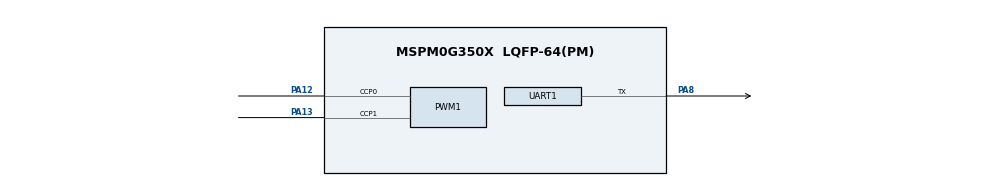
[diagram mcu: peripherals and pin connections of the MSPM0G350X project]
/**
 * @cliArgs --device "MSPM0G350X" --package "LQFP-64(PM)" --part "Default" --product "mspm0_sdk@2.01.00.03"
 * @versions {"tool":"1.20.0+3587"}
 */

/**
 * Import the modules used in this configuration.
 */
const GPIO   = scripting.addModule("/ti/driverlib/GPIO", {}, false);
const GPIO1  = GPIO.addInstance();
const GPIO2  = GPIO.addInstance();
const GPIO3  = GPIO.addInstance();
const GPIO4  = GPIO.addInstance();
const GPIO5  = GPIO.addInstance();
const GPIO6  = GPIO.addInstance();
const GPIO7  = GPIO.addInstance();
const GPIO8  = GPIO.addInstance();
const PWM    = scripting.addModule("/ti/driverlib/PWM", {}, false);
const PWM1   = PWM.addInstance();
const SYSCTL = scripting.addModule("/ti/driverlib/SYSCTL");
const TIMER  = scripting.addModule("/ti/driverlib/TIMER", {}, false);
const TIMER1 = TIMER.addInstance();
const UART   = scripting.addModule("/ti/driverlib/UART", {}, false);
const UART1  = UART.addInstance();

/**
 * Write custom configuration values to the imported modules.
 */
GPIO1.$name                          = "GPIO_OLED";
GPIO1.associatedPins.create(2);
GPIO1.associatedPins[0].$name        = "SCL";
GPIO1.associatedPins[0].initialValue = "SET";
GPIO1.associatedPins[0].assignedPort = "PORTB";
GPIO1.associatedPins[0].assignedPin  = "6";
GPIO1.associatedPins[1].$name        = "SDA";
GPIO1.associatedPins[1].initialValue = "SET";
GPIO1.associatedPins[1].assignedPort = "PORTB";
GPIO1.associatedPins[1].assignedPin  = "1";

const Board = scripting.addModule("/ti/driverlib/Board", {}, false);

GPIO2.$name                          = "GPIO_LEFT_DIR";
GPIO2.associatedPins.create(2);
GPIO2.associatedPins[0].assignedPort = "PORTA";
GPIO2.associatedPins[0].assignedPin  = "28";
GPIO2.associatedPins[0].$name        = "IN1";
GPIO2.associatedPins[1].assignedPort = "PORTA";
GPIO2.associatedPins[1].assignedPin  = "31";
GPIO2.associatedPins[1].$name        = "IN2";

GPIO3.$name                          = "GPIO_RIGHT_DIR";
GPIO3.associatedPins.create(2);
GPIO3.associatedPins[0].$name        = "IN3";
GPIO3.associatedPins[0].assignedPort = "PORTB";
GPIO3.associatedPins[0].assignedPin  = "12";
GPIO3.associatedPins[1].$name        = "IN4";
GPIO3.associatedPins[1].assignedPort = "PORTB";
GPIO3.associatedPins[1].assignedPin  = "17";

GPIO4.$name                               = "GPIO_ECD";
GPIO4.associatedPins.create(4);
GPIO4.associatedPins[0].direction         = "INPUT";
GPIO4.associatedPins[0].assignedPort      = "PORTB";
GPIO4.associatedPins[0].assignedPin       = "15";
GPIO4.associatedPins[0].interruptEn       = true;
GPIO4.associatedPins[0].interruptPriority = "0";
GPIO4.associatedPins[0].polarity          = "RISE";
GPIO4.associatedPins[0].$name             = "LEFT_A";
GPIO4.associatedPins[1].direction         = "INPUT";
GPIO4.associatedPins[1].assignedPort      = "PORTB";
GPIO4.associatedPins[1].assignedPin       = "13";
GPIO4.associatedPins[1].polarity          = "RISE";
GPIO4.associatedPins[1].interruptEn       = true;
GPIO4.associatedPins[1].interruptPriority = "0";
GPIO4.associatedPins[1].$name             = "LEFT_B";
GPIO4.associatedPins[2].$name             = "RIGH_A";
GPIO4.associatedPins[2].direction         = "INPUT";
GPIO4.associatedPins[2].interruptEn       = true;
GPIO4.associatedPins[2].interruptPriority = "0";
GPIO4.associatedPins[2].polarity          = "RISE";
GPIO4.associatedPins[2].assignedPort      = "PORTB";
GPIO4.associatedPins[2].assignedPin       = "8";
GPIO4.associatedPins[3].$name             = "RIGH_B";
GPIO4.associatedPins[3].direction         = "INPUT";
GPIO4.associatedPins[3].assignedPort      = "PORTB";
GPIO4.associatedPins[3].assignedPin       = "7";
GPIO4.associatedPins[3].interruptEn       = true;
GPIO4.associatedPins[3].interruptPriority = "0";
GPIO4.associatedPins[3].polarity          = "RISE";

GPIO5.$name                          = "GPIO_TRK";
GPIO5.associatedPins.create(8);
GPIO5.associatedPins[0].$name        = "P0";
GPIO5.associatedPins[0].direction    = "INPUT";
GPIO5.associatedPins[0].assignedPort = "PORTB";
GPIO5.associatedPins[0].assignedPin  = "18";
GPIO5.associatedPins[1].$name        = "P1";
GPIO5.associatedPins[1].direction    = "INPUT";
GPIO5.associatedPins[1].assignedPort = "PORTB";
GPIO5.associatedPins[1].assignedPin  = "19";
GPIO5.associatedPins[2].$name        = "P2";
GPIO5.associatedPins[2].direction    = "INPUT";
GPIO5.associatedPins[2].assignedPort = "PORTB";
GPIO5.associatedPins[2].assignedPin  = "20";
GPIO5.associatedPins[3].$name        = "P3";
GPIO5.associatedPins[3].direction    = "INPUT";
GPIO5.associatedPins[3].assignedPort = "PORTB";
GPIO5.associatedPins[3].assignedPin  = "21";
GPIO5.associatedPins[4].$name        = "P4";
GPIO5.associatedPins[4].direction    = "INPUT";
GPIO5.associatedPins[4].assignedPort = "PORTB";
GPIO5.associatedPins[4].assignedPin  = "22";
GPIO5.associatedPins[5].$name        = "P5";
GPIO5.associatedPins[5].direction    = "INPUT";
GPIO5.associatedPins[5].assignedPort = "PORTB";
GPIO5.associatedPins[5].assignedPin  = "23";
GPIO5.associatedPins[6].$name        = "P6";
GPIO5.associatedPins[6].direction    = "INPUT";
GPIO5.associatedPins[6].assignedPort = "PORTB";
GPIO5.associatedPins[6].assignedPin  = "24";
GPIO5.associatedPins[7].$name        = "P7";
GPIO5.associatedPins[7].direction    = "INPUT";
GPIO5.associatedPins[7].assignedPort = "PORTB";
GPIO5.associatedPins[7].assignedPin  = "25";

GPIO6.$name                              = "GPIO_KEY";
GPIO6.associatedPins.create(3);
GPIO6.associatedPins[0].direction        = "INPUT";
GPIO6.associatedPins[0].internalResistor = "PULL_UP";
GPIO6.associatedPins[0].assignedPort     = "PORTA";
GPIO6.associatedPins[0].assignedPin      = "14";
GPIO6.associatedPins[0].$name            = "add";
GPIO6.associatedPins[1].$name            = "enter";
GPIO6.associatedPins[1].direction        = "INPUT";
GPIO6.associatedPins[1].internalResistor = "PULL_UP";
GPIO6.associatedPins[1].assignedPort     = "PORTA";
GPIO6.associatedPins[1].assignedPin      = "15";
GPIO6.associatedPins[2].$name            = "xxx";
GPIO6.associatedPins[2].direction        = "INPUT";
GPIO6.associatedPins[2].internalResistor = "PULL_UP";
GPIO6.associatedPins[2].assignedPort     = "PORTA";
GPIO6.associatedPins[2].assignedPin      = "16";

GPIO7.$name                          = "GPIO_JDQ";
GPIO7.associatedPins[0].$name        = "JDQ1";
GPIO7.associatedPins[0].assignedPort = "PORTA";
GPIO7.associatedPins[0].assignedPin  = "27";

GPIO8.$name                              = "GPIO_FAKE";
GPIO8.associatedPins.create(2);
GPIO8.associatedPins[0].$name            = "IN";
GPIO8.associatedPins[0].direction        = "INPUT";
GPIO8.associatedPins[0].internalResistor = "PULL_UP";
GPIO8.associatedPins[0].assignedPort     = "PORTA";
GPIO8.associatedPins[0].assignedPin      = "24";
GPIO8.associatedPins[1].$name            = "OUT";
GPIO8.associatedPins[1].assignedPort     = "PORTA";
GPIO8.associatedPins[1].assignedPin      = "25";

PWM1.$name                              = "PWM_MOTO";
PWM1.pwmMode                            = "EDGE_ALIGN_UP";
PWM1.peripheral.ccp0Pin.$assign         = "PA12";
PWM1.peripheral.ccp1Pin.$assign         = "PA13";
PWM1.PWM_CHANNEL_0.$name                = "ti_driverlib_pwm_PWMTimerCC0";
PWM1.PWM_CHANNEL_1.$name                = "ti_driverlib_pwm_PWMTimerCC1";
PWM1.ccp0PinConfig.$name                = "ti_driverlib_gpio_GPIOPinGeneric0";
PWM1.ccp0PinConfig.direction            = scripting.forceWrite("OUTPUT");
PWM1.ccp0PinConfig.hideOutputInversion  = scripting.forceWrite(false);
PWM1.ccp0PinConfig.onlyInternalResistor = scripting.forceWrite(false);
PWM1.ccp0PinConfig.passedPeripheralType = scripting.forceWrite("Digital");
PWM1.ccp0PinConfig.enableConfig         = true;
PWM1.ccp0PinConfig.internalResistor     = "PULL_DOWN";
PWM1.ccp1PinConfig.$name                = "ti_driverlib_gpio_GPIOPinGeneric1";
PWM1.ccp1PinConfig.direction            = scripting.forceWrite("OUTPUT");
PWM1.ccp1PinConfig.hideOutputInversion  = scripting.forceWrite(false);
PWM1.ccp1PinConfig.onlyInternalResistor = scripting.forceWrite(false);
PWM1.ccp1PinConfig.passedPeripheralType = scripting.forceWrite("Digital");
PWM1.ccp1PinConfig.enableConfig         = true;
PWM1.ccp1PinConfig.internalResistor     = "PULL_DOWN";

SYSCTL.forceDefaultClkConfig = true;

TIMER1.$name       = "TIMER_CTRL";
TIMER1.timerClkDiv = 8;
TIMER1.timerMode   = "PERIODIC_UP";
TIMER1.interrupts  = ["LOAD"];
TIMER1.timerPeriod = "5 ms";

UART1.$name                            = "UART_LX225";
UART1.targetBaudRate                   = 115200;
UART1.direction                        = "TX";
UART1.peripheral.$assign               = "UART1";
UART1.peripheral.txPin.$assign         = "PA8";
UART1.txPinConfig.$name                = "ti_driverlib_gpio_GPIOPinGeneric2";
UART1.txPinConfig.direction            = scripting.forceWrite("OUTPUT");
UART1.txPinConfig.hideOutputInversion  = scripting.forceWrite(false);
UART1.txPinConfig.onlyInternalResistor = scripting.forceWrite(false);
UART1.txPinConfig.passedPeripheralType = scripting.forceWrite("Digital");
UART1.txPinConfig.enableConfig         = true;
UART1.txPinConfig.internalResistor     = "PULL_UP";

/**
 * Pinmux solution for unlocked pins/peripherals. This ensures that minor changes to the automatic solver in a future
 * version of the tool will not impact the pinmux you originally saw.  These lines can be completely deleted in order to
 * re-solve from scratch.
 */
GPIO1.associatedPins[0].pin.$suggestSolution = "PB6";
GPIO1.associatedPins[1].pin.$suggestSolution = "PB1";
Board.peripheral.$suggestSolution            = "DEBUGSS";
Board.peripheral.swclkPin.$suggestSolution   = "PA20";
Board.peripheral.swdioPin.$suggestSolution   = "PA19";
GPIO2.associatedPins[0].pin.$suggestSolution = "PA28";
GPIO2.associatedPins[1].pin.$suggestSolution = "PA31";
GPIO3.associatedPins[0].pin.$suggestSolution = "PB12";
GPIO3.associatedPins[1].pin.$suggestSolution = "PB17";
GPIO4.associatedPins[0].pin.$suggestSolution = "PB15";
GPIO4.associatedPins[1].pin.$suggestSolution = "PB13";
GPIO4.associatedPins[2].pin.$suggestSolution = "PB8";
GPIO4.associatedPins[3].pin.$suggestSolution = "PB7";
GPIO5.associatedPins[0].pin.$suggestSolution = "PB18";
GPIO5.associatedPins[1].pin.$suggestSolution = "PB19";
GPIO5.associatedPins[2].pin.$suggestSolution = "PB20";
GPIO5.associatedPins[3].pin.$suggestSolution = "PB21";
GPIO5.associatedPins[4].pin.$suggestSolution = "PB22";
GPIO5.associatedPins[5].pin.$suggestSolution = "PB23";
GPIO5.associatedPins[6].pin.$suggestSolution = "PB24";
GPIO5.associatedPins[7].pin.$suggestSolution = "PB25";
GPIO6.associatedPins[0].pin.$suggestSolution = "PA14";
GPIO6.associatedPins[1].pin.$suggestSolution = "PA15";
GPIO6.associatedPins[2].pin.$suggestSolution = "PA16";
GPIO7.associatedPins[0].pin.$suggestSolution = "PA27";
GPIO8.associatedPins[0].pin.$suggestSolution = "PA24";
GPIO8.associatedPins[1].pin.$suggestSolution = "PA25";
PWM1.peripheral.$suggestSolution             = "TIMG0";
SYSCTL.peripheral.$suggestSolution           = "SYSCTL";
TIMER1.peripheral.$suggestSolution           = "TIMA0";
